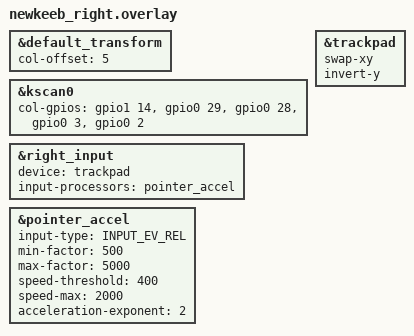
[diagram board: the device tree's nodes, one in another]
/*
 * RIGHT half = split PERIPHERAL (forced ROLE_CENTRAL=n in build.yaml).
 * Local trackpad -> POINTER, forwarded to the dongle. Occupies cols 5-9.
 */

#include "newkeeb_half.dtsi"
#include <zephyr/dt-bindings/input/input-event-codes.h>
#include <behaviors/input_gestures_accel.dtsi>

/* Right half occupies columns 5-9 of the combined transform. */
&default_transform {
    col-offset = <5>;
};

/*
 * Wire BOTH halves identically (mirror images): on each hand the OUTER column
 * goes to the D0 bus ... the INNER column (by the gap) goes to D9 / P1.14.
 * The right hand is a left-right mirror, so its column scan order is reversed
 * here and the keymap still reads left-to-right. Rows are NOT reversed.
 */
&kscan0 {
    col-gpios
        = <&gpio1 14 GPIO_ACTIVE_HIGH>   /* inner (by gap)  D9  P1.14  -> logical col5 (Y) */
        , <&gpio0 29 GPIO_ACTIVE_HIGH>   /*                 D3  P0.29  -> logical col6 (U) */
        , <&gpio0 28 GPIO_ACTIVE_HIGH>   /*                 D2  P0.28  -> logical col7 (I) */
        , <&gpio0  3 GPIO_ACTIVE_HIGH>   /*                 D1  P0.03  -> logical col8 (O) */
        , <&gpio0  2 GPIO_ACTIVE_HIGH>   /* outer (far R)   D0  P0.02  -> logical col9 (P) */
        ;
};

/*
 * Forward this half's pad to the pointer proxy, ACCELERATED HERE on the
 * peripheral. Velocity acceleration needs accurate per-event timing; on the
 * dongle the events arrive over BLE in bursts so the computed speed is garbage
 * and the accel does nothing. Processing on the peripheral (where the pad is)
 * fixes that. The dongle only maps/temp-layers the already-accelerated motion.
 */
&right_input {
    status = "okay";
    device = <&trackpad>;
    input-processors = <&pointer_accel>;
};

/*
 * Axis orientation for the RIGHT pad.
 * Set to swap-xy; invert-y; so Up/Down and Left/Right match screen direction.
 */
&trackpad {
    swap-xy;
    invert-y;
};

/*
 * Pointer acceleration curve (factors x1000):
 *   speed 0 -> min-factor,  speed=threshold -> 1.0x,  speed>=speed-max -> max-factor
 * min-factor < 1000 gives precise slow aiming; the ramp to max-factor is the feel.
 * Speed is counts/sec; a Cirque tops ~2-3k cps, so speed-max sits in that range.
 */
&pointer_accel {
    input-type = <INPUT_EV_REL>;
    min-factor = <500>;       /* 0.5x slow -> micro-precision */
    max-factor = <5000>;      /* 5.0x fast flick -> strong acceleration surge */
    speed-threshold = <400>;  /* 400 counts/sec threshold */
    speed-max = <2000>;       /* 2000 counts/sec max speed threshold */
    acceleration-exponent = <2>; /* Quadratic curve */
};
